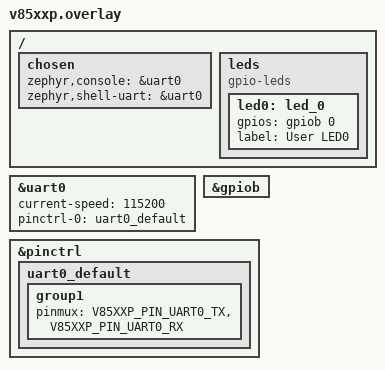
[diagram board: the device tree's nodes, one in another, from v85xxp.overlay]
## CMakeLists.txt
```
cmake_minimum_required(VERSION 3.20.0)
# --- HWMv2 FORCED PATH (SURGICAL FIX) ---
if(NOT DEFINED BOARD_ROOT)
    set(BOARD_ROOT /root/fast_space/modules/soc/v32f20x /workspaces/modules/soc/v32f20x)
endif()
if(NOT DEFINED SOC_ROOT)
    set(SOC_ROOT /root/fast_space/modules/soc/v32f20x /workspaces/modules/soc/v32f20x)
endif()
if(BOARD STREQUAL "v32f20x_board/v32f20x/cpuapp")
    set(BOARD v32f20x_board/v32f20x/cpuapp/cpuapp CACHE STRING "" FORCE)
endif()
# ----------------------------------------

# 1. Target Profile Loading (Building a repeatable preset system)
if(TARGET_NAME)
    set(TARGET_PATH ${CMAKE_CURRENT_LIST_DIR}/targets/${TARGET_NAME})
    if(EXISTS ${TARGET_PATH}/target.cmake)
        message(STATUS "--> Loading Target Profile: ${TARGET_NAME}")
        include(${TARGET_PATH}/target.cmake)
    else()
        message(FATAL_ERROR "Target profile ${TARGET_NAME} not found in targets/ directory.")
    endif()
endif()

find_package(Zephyr REQUIRED HINTS $ENV{ZEPHYR_BASE})
project(vango_demo)

# 2. Main Orchestrator
target_sources(app PRIVATE 
    src/main.c
    src/services/ipc_service.c
    src/services/power_monitor.c
    src/services/storage_init.c
    src/drivers/watchdog.c
    src/drivers/boot_cpu1.c
)

# 3. Capability-based Service Inclusion
# Sources are linked only if the corresponding Kconfig is enabled in prj.conf
target_sources_ifdef(CONFIG_APP_FEATURE_METERING  app PRIVATE src/services/metering.c)
target_sources_ifdef(CONFIG_APP_FEATURE_COMMS     app PRIVATE src/services/comms.c)
target_sources_ifdef(CONFIG_MODBUS                app PRIVATE src/services/modbus_service.c)
target_sources_ifdef(CONFIG_NETWORKING            app PRIVATE src/services/network_service.c)
target_sources_ifdef(CONFIG_APP_FEATURE_SECURITY  app PRIVATE src/services/security.c)
target_sources_ifdef(CONFIG_APP_FEATURE_LOW_POWER app PRIVATE src/services/low_power.c)
target_sources_ifdef(CONFIG_APP_FEATURE_OTA       app PRIVATE src/services/ota_service.c)

# 4. Global Includes
target_include_directories(app PRIVATE 
    src
    /workspaces/applications/lib/flashdb/src/inc
    /workspaces/applications/lib/flashdb/port
)

# 5. WASM Sandbox WAMR Integration
target_sources_ifdef(CONFIG_APP_FEATURE_WASM_SANDBOX app PRIVATE src/services/wasm_sandbox.c)

if(CONFIG_APP_FEATURE_WASM_SANDBOX)
    set(WAMR_ROOT_DIR "/workspaces/vendor/AkiraOS/modules/wasm-micro-runtime")
    set(WAMR_BUILD_PLATFORM "zephyr")
    set(WAMR_BUILD_TARGET "THUMB_V7")
    set(WAMR_BUILD_INTERP 1)
    set(WAMR_BUILD_MINI_LOADER 1)
    set(WAMR_BUILD_AOT 0)
    set(WAMR_BUILD_LIBC_BUILTIN 1)
    set(WAMR_BUILD_LIBC_WASI 0)
    set(WAMR_BUILD_GLOBAL_HEAP_POOL 1)
    set(WAMR_BUILD_GLOBAL_HEAP_SIZE 65536)
    set(WAMR_BUILD_REF_TYPES 0)
    
    include(${WAMR_ROOT_DIR}/build-scripts/runtime_lib.cmake)
    target_sources(app PRIVATE ${WAMR_RUNTIME_LIB_SOURCE})
    target_include_directories(app PRIVATE
        ${WAMR_ROOT_DIR}/core/iwasm/include
        ${WAMR_ROOT_DIR}/core/shared
        ${WAMR_ROOT_DIR}/core/deps
        src/services
    )
endif()
```

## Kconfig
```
# Vango Demo Application Configuration

# 1. Essential: Source Zephyr's main Kconfig to inherit all system symbols (ADC, GPIO, etc.)
mainmenu "Vango Target-Centric Demo"

source "Kconfig.zephyr"

# 2. Application-specific Capabilities
menu "Vango Demo Capabilities"

config APP_FEATURE_METERING
	bool "Enable Metering Service"
	default n
	help
	  Enable high-frequency energy sampling using ADC/EADC.

config APP_FEATURE_COMMS
	bool "Enable Communication Gateway Service"
	default n
	help
	  Enable communication stacks (Ethernet, USB, Flexcomm) and gateway logic.

config APP_FEATURE_SECURITY
	bool "Enable Security & Crypto Service"
	default n
	help
	  Enable hardware encryption (AES/SHA) engine demonstrations.

config APP_FEATURE_LOW_POWER
	bool "Enable Low Power Monitor Service"
	default n
	help
	  Enable UART32K and PMU sleep state management (V85XXP focus).

config APP_FEATURE_OTA
	bool "Enable MCUboot OTA Readiness Service"
	default n
	help
	  Enable firmware download simulator and MCUboot upgrade request APIs.

config APP_FEATURE_WASM_SANDBOX
	bool "Enable Lightweight WASM Business Isolation Sandbox"
	default n
	help
	  Enable WAMR runtime and a dedicated sandboxed execution environment.

endmenu
```

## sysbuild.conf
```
SB_CONFIG_BOOTLOADER_MCUBOOT=y
SB_CONFIG_BOOT_SWAP_USING_SCRATCH=y
SB_CONFIG_MCUBOOT_IMAGE_NUMBER=2
```

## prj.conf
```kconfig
# Base configuration for vango_demo
CONFIG_LOG=y
CONFIG_APP_FEATURE_METERING=y
CONFIG_APP_FEATURE_COMMS=y

# Power Management
CONFIG_PM=y
CONFIG_PM_DEVICE=y
CONFIG_PM_DEVICE_RUNTIME=y

# Base Hardware Support
CONFIG_SERIAL=y
CONFIG_GPIO=y
CONFIG_ADC=y

# WASM Sandbox
CONFIG_APP_FEATURE_WASM_SANDBOX=y
CONFIG_HEAP_MEM_POOL_SIZE=49152
```

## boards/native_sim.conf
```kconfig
# 开启模拟器子系统
CONFIG_EMUL=y

# 开启 ADC 子系统及 ADC 模拟器驱动
CONFIG_ADC=y
CONFIG_ADC_EMUL=y

# 开启 UART 子系统（native_sim 默认已开，这里确保开启）
CONFIG_SERIAL=y

# OTA & janpatch 测试
CONFIG_APP_FEATURE_OTA=y
CONFIG_JANPATCH=y
CONFIG_SHELL=y
CONFIG_HEAP_MEM_POOL_SIZE=49152
```

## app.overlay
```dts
/*
 * Copyright (c) 2024 Vango Technologies
 * SPDX-License-Identifier: Apache-2.0
 */

/ {
    chosen {
        /* CPU0 (CM0) Professional choice: use standalone UART14 for console */
        zephyr,console = &uart14;
        zephyr,shell-uart = &uart14;
    };
};

/* Enable ADC0 for sampling demo */
&adc0 {
    status = "okay";
};

/* Enable standalone UART14 for CM0 Console */
&uart14 {
    status = "okay";
    current-speed = <115200>;
    pinctrl-0 = <&uart14_default>;
    pinctrl-names = "default";
};

/* Custom Pinctrl for the Demo */
&pinctrl {
    uart14_default: uart14_default {
        group1 {
            pinmux = <VANGO_PINMUX(VANGO_PORT_C, 10, 1)>, /* UART14_TX on PC10 AF1 */
                     <VANGO_PINMUX(VANGO_PORT_C, 11, 1)>; /* UART14_RX on PC11 AF1 */
        };
    };
};
```

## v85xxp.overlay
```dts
/*
 * Copyright (c) 2026 Vango Technologies
 * SPDX-License-Identifier: Apache-2.0
 */

#include <zephyr/dt-bindings/gpio/gpio.h>
#include <zephyr/dt-bindings/pinctrl/vango-v85xxp-pinctrl.h>

/ {
	chosen {
		zephyr,console = &uart0;
		zephyr,shell-uart = &uart0;
	};

	leds {
		compatible = "gpio-leds";
		led0: led_0 {
			gpios = <&gpiob 0 GPIO_ACTIVE_HIGH>;
			label = "User LED0";
		};
	};
};

&uart0 {
	status = "okay";
	current-speed = <115200>;
	pinctrl-0 = <&uart0_default>;
	pinctrl-names = "default";
};

&gpiob {
	status = "okay";
};

&pinctrl {
	uart0_default: uart0_default {
		group1 {
			pinmux = <V85XXP_PIN_UART0_TX>, <V85XXP_PIN_UART0_RX>;
		};
	};
};
```

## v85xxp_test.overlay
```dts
/ {
    chosen {
        /* 使用我们新修复的 UART0 进行控制台输出 */
        zephyr,console = &uart0;
        zephyr,shell-uart = &uart0;
    };
};

&uart0 {
    status = "okay";
    current-speed = <115200>;
    /* 使用我们刚补全的 100+ 个宏中的 UART0 专用宏 */
    pinctrl-0 = <&uart0_default>;
    pinctrl-names = "default";
};

&pinctrl {
    uart0_default: uart0_default {
        group1 {
            /* 现在的宏定义已经是标准的 VANGO_PINMUX 编码了 */
            pinmux = <V85XXP_PIN_UART0_TX>, <V85XXP_PIN_UART0_RX>;
        };
    };
};
```

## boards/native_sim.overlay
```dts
/ {
	aliases {
		/* 将业务代码中的 ADC 宏重定向到 Zephyr 的官方 ADC 模拟器 */
		app-adc = &adc_emul;
		/* 将业务代码中的 UART 重定向到 Linux 模拟器的第二个串口 (Pseudoterminal) */
		app-uart = &uart1;
	};

	/* 实例化一个纯软件的 ADC 模拟外设 */
	adc_emul: adc_emul {
		compatible = "zephyr,adc-emul";
		nchannels = <4>;
		ref-internal-mv = <3300>;
		#io-channel-cells = <1>;
		status = "okay";
	};
};

/* 激活 Linux 原生的 UART1 */
&uart1 {
	status = "okay";
	current-speed = <115200>;
};
```

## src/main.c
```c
/*
 * Unified Application Orchestrator
 * (SoC-agnostic, capability-driven)
 */
#include <zephyr/kernel.h>
#include <zephyr/logging/log.h>
#include <string.h>

LOG_MODULE_REGISTER(app_main, LOG_LEVEL_INF);

#if defined(CONFIG_SOC_V32F20X_CPUAPP)
#include <zephyr/sys/reboot.h>
extern void boot_cpu1(void);
#endif

extern int ipc_service_init(void);
#ifdef CONFIG_APP_FEATURE_LOW_POWER
extern int power_monitor_init(void);
extern int low_power_init(void);
#endif
#ifdef CONFIG_APP_FEATURE_OTA
extern int ota_service_init(void);
#endif
extern int security_service_init(void);
extern int watchdog_init(void);
extern void watchdog_feed(void);

#if defined(CONFIG_SOC_V32F20X_CPUMETER)
#include <protocol.h>
extern int ipc_send_metering(struct metering_payload *payload);
extern int ipc_send_waveform_ptr(struct waveform_ptr_payload *payload);
#endif

int main(void)
{
        LOG_INF("============================================");
        LOG_INF("  Vango Target-Centric App Orchestrator");
        LOG_INF("  Build: %s %s", __DATE__, __TIME__);
        LOG_INF("============================================");

#if defined(CONFIG_SOC_V32F20X_CPUAPP)
    LOG_INF("Core: CPUAPP (Cortex-M33 Primary Core)");
    LOG_INF("Booting CPU1 (cpumeter) from separate sysbuild image...");
    boot_cpu1();
#elif defined(CONFIG_SOC_V32F20X_CPUMETER)
    LOG_INF("Core: CPUMETER (Cortex-M0 Secondary Core)");
#endif

    /* Initialize Services (Note: FlashDB is now handled via SYS_INIT) */
    watchdog_init();
    ipc_service_init();
#ifdef CONFIG_APP_FEATURE_LOW_POWER
    power_monitor_init();
    low_power_init();
#endif
#ifdef CONFIG_APP_FEATURE_OTA
    ota_service_init();
#endif
#ifdef CONFIG_APP_FEATURE_SECURITY
    security_service_init();
#endif
#ifdef CONFIG_APP_FEATURE_WASM_SANDBOX
    extern int wasm_sandbox_init(void);
    wasm_sandbox_init();
#endif

#if defined(CONFIG_SOC_V32F20X_CPUMETER)
    struct metering_payload mp = {0};
    struct waveform_ptr_payload wp = {
        .shm_address = WAVEFORM_SHM_BASE,
        .sample_cnt = 512,
        .channel_mask = 0x07
    };
#endif

        while (1) {
                watchdog_feed();
        #if defined(CONFIG_SOC_V32F20X_CPUMETER)
                /* 1. Periodic Standard Metering Data */
                mp.active_energy += 10;
                mp.reactive_energy += 5;
                mp.timestamp = k_uptime_get_32();
                ipc_send_metering(&mp);

                /* 2. Zero-copy Waveform Event */
                ipc_send_waveform_ptr(&wp);
        #endif
                k_msleep(10000);
        }
        return 0;
}
```

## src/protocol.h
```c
#ifndef PROTOCOL_H
#define PROTOCOL_H

#include <stdint.h>

struct metering_data {
    uint32_t active_energy;
    uint32_t reactive_energy;
    uint32_t timestamp;
};

#endif
```
